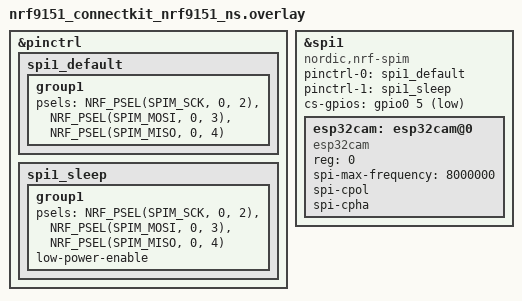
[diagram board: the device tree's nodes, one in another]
/*
 * Copyright (c) 2023 Nordic Semiconductor ASA
 *
 * SPDX-License-Identifier: LicenseRef-Nordic-5-Clause
 */

&pinctrl {
	spi1_default: spi1_default {
		group1 {
			psels = <NRF_PSEL(SPIM_SCK, 0, 2)>,
				<NRF_PSEL(SPIM_MOSI, 0, 3)>,
				<NRF_PSEL(SPIM_MISO, 0, 4)>;
		};
	};

	spi1_sleep: spi1_sleep {
		group1 {
			psels = <NRF_PSEL(SPIM_SCK, 0, 2)>,
				<NRF_PSEL(SPIM_MOSI, 0, 3)>,
				<NRF_PSEL(SPIM_MISO, 0, 4)>;
			low-power-enable;
		};
	};
};

&spi1 {
	status = "okay";
	compatible = "nordic,nrf-spim";
	pinctrl-0 = <&spi1_default>;
	pinctrl-1 = <&spi1_sleep>;
	pinctrl-names = "default", "sleep";
	cs-gpios = <&gpio0 5 GPIO_ACTIVE_LOW>;

	esp32cam: esp32cam@0 {
		status = "okay";
		compatible = "esp32cam";
		reg = <0>;
		spi-max-frequency = <8000000>;
		spi-cpol;
		spi-cpha;
	};
};
